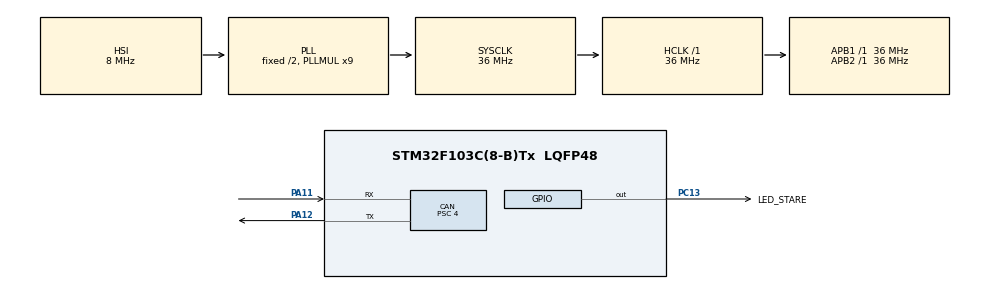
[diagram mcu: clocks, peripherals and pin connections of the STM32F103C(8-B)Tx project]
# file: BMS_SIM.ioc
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CAN.BS1=CAN_BS1_15TQ
CAN.BS2=CAN_BS2_2TQ
CAN.CalculateBaudRate=500000
CAN.CalculateTimeBit=2000
CAN.CalculateTimeQuantum=111.11111111111111
CAN.Prescaler=4
Mcu.Family=STM32F1
Mcu.Name=STM32F103C(8-B)Tx
Mcu.Package=LQFP48
NVIC.CAN1_RX1_IRQn=true\:0\:0\:false\:false\:true\:true\:true\:true
NVIC.CAN1_SCE_IRQn=true\:0\:0\:false\:false\:true\:true\:true\:true
NVIC.PriorityGroup=NVIC_PRIORITYGROUP_4
NVIC.TIM2_IRQn=true\:0\:0\:false\:false\:true\:true\:true\:true
NVIC.TIM3_IRQn=true\:0\:0\:false\:false\:true\:true\:true\:true
NVIC.USB_HP_CAN1_TX_IRQn=true\:0\:0\:false\:false\:true\:true\:true\:true
NVIC.USB_LP_CAN1_RX0_IRQn=true\:0\:0\:false\:false\:true\:true\:true\:true
PA11.Mode=CAN_Activate
PA11.Signal=CAN_RX
PA12.Mode=CAN_Activate
PA12.Signal=CAN_TX
PC13-TAMPER-RTC.GPIO_Label=LED_STARE
PC13-TAMPER-RTC.Signal=GPIO_Output
ProjectManager.HeapSize=0x200
ProjectManager.StackSize=0x400
ProjectManager.TargetToolchain=STM32CubeIDE
RCC.AHBFreq_Value=36000000
RCC.APB1Freq_Value=36000000
RCC.APB1TimFreq_Value=36000000
RCC.APB2Freq_Value=36000000
RCC.APB2TimFreq_Value=36000000
RCC.HCLKFreq_Value=36000000
RCC.PLLMUL=RCC_PLL_MUL9
RCC.SYSCLKFreq_VALUE=36000000
RCC.SYSCLKSource=RCC_SYSCLKSOURCE_PLLCLK
RCC.USBFreq_Value=36000000
TIM2.Period=49999
TIM2.Prescaler=399
TIM3.Period=44999
TIM3.Prescaler=399
VP_SYS_VS_ND.Mode=No_Debug
VP_TIM2_VS_ClockSourceINT.Mode=Internal
VP_TIM3_VS_ClockSourceINT.Mode=Internal
board=custom

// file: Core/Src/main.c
/* USER CODE BEGIN Header */
/**
 ******************************************************************************
 * @file           : main.c
 * @brief          : Main program body
 ******************************************************************************
 * @attention
 *
 * Copyright (c) 2025 STMicroelectronics.
 * All rights reserved.
 *
 * This software is licensed under terms that can be found in the LICENSE file
 * in the root directory of this software component.
 * If no LICENSE file comes with this software, it is provided AS-IS.
 *
 ******************************************************************************
 */
/* USER CODE END Header */
#include "main.h"

/* USER CODE BEGIN Includes */
#include <stdbool.h>
/* USER CODE END Includes */

CAN_HandleTypeDef hcan;

TIM_HandleTypeDef htim2;
TIM_HandleTypeDef htim3;

/* USER CODE BEGIN PV */
volatile bool tim2_flag_b = 0;
volatile bool tim3_flag_b = 0;
/* USER CODE END PV */

void SystemClock_Config(void);
static void MX_GPIO_Init(void);
static void MX_TIM2_Init(void);
static void MX_TIM3_Init(void);
static void MX_CAN_Init(void);

/* USER CODE BEGIN 0 */
void CAN_TX(uint32_t StdId, uint32_t DLC, const uint8_t *Data) {
	CAN_TxHeaderTypeDef txheader;
	uint32_t txmailbox;

	txheader.DLC = DLC;
	txheader.StdId = StdId;
	txheader.IDE = CAN_ID_STD;
	txheader.RTR = CAN_RTR_DATA;

	if (HAL_CAN_AddTxMessage(&hcan, &txheader, Data, &txmailbox) != HAL_OK) {
		Error_Handler();
	}
}
/* USER CODE END 0 */

int main(void)
{

  /* MCU Configuration--------------------------------------------------------*/

  /* Reset of all peripherals, Initializes the Flash interface and the Systick. */
  HAL_Init();

  /* Configure the system clock */
  SystemClock_Config();

  /* Initialize all configured peripherals */
  MX_GPIO_Init();
  MX_TIM2_Init();
  MX_TIM3_Init();
  MX_CAN_Init();
  /* USER CODE BEGIN 2 */
	if (HAL_CAN_ActivateNotification(&hcan,
		CAN_IT_TX_MAILBOX_EMPTY | CAN_IT_RX_FIFO0_MSG_PENDING | CAN_IT_BUSOFF)
				!= HAL_OK) {
			Error_Handler();
		}

		if (HAL_CAN_Start(&hcan) != HAL_OK) {
			Error_Handler();
		}
	HAL_TIM_Base_Start_IT(&htim2);
	HAL_TIM_Base_Start_IT(&htim3);

  /* USER CODE END 2 */

  /* Infinite loop */
	while (1) {

    /* USER CODE BEGIN 3 */
		if (tim2_flag_b == 1) {
			HAL_GPIO_TogglePin(LED_STARE_GPIO_Port, LED_STARE_Pin);

			uint8_t Data_100[8] = {
			    0x01, 0xF4,  // Voltage (500 -> 50.0V)
			    0x00, 0x64,  // Current (100 -> 10.0A)
			    0x50,        // SOC (80%)
			    0x63,        // SOH (99%)
			    0xFA,        // AmpHours (250 -> 25.0Ah)
			    0x0E         // CRC Checksum
			};
			CAN_TX(0x100, 8, Data_100);

			tim2_flag_b = 0;
		}
		if (tim3_flag_b == 1) {
			HAL_GPIO_TogglePin(LED_STARE_GPIO_Port, LED_STARE_Pin);
			uint8_t Data_101[8] = {
			    0x28,        // High Temp (40 C)
			    0x01,        // High ID
			    0x19,        // Low Temp (25 C)
			    0x02,        // Low ID
			    0x1E,        // Avg Temp (30 C)
			    0x05,        // Fan Speed
			    0x78,        // Fan Voltage (120 -> 12.0V)
			    0xE8         // CRC Checksum
			};
			CAN_TX(0x101, 8, Data_101);

			uint8_t Data_102[8] = {
			    0x00, 0x32,  // Resistance (50 mOhm)
			    0x02, 0x08,  // Max Pack Voltage (520 -> 52.0V)
			    0x96,        // Total Cycles (150)
			    0x23,        // Internal Temp (35 C)
			    0x03,        // Req Fan Speed
			    0x02         // CRC Checksum
			};
				CAN_TX(0x102, 8, Data_102);
				tim3_flag_b = 0;
			}

	}

  /* USER CODE END 3 */
}

void SystemClock_Config(void)
{
  RCC_OscInitTypeDef RCC_OscInitStruct = {0};
  RCC_ClkInitTypeDef RCC_ClkInitStruct = {0};

  /** Initializes the RCC Oscillators according to the specified parameters
  * in the RCC_OscInitTypeDef structure.
  */
  RCC_OscInitStruct.OscillatorType = RCC_OSCILLATORTYPE_HSI;
  RCC_OscInitStruct.HSIState = RCC_HSI_ON;
  RCC_OscInitStruct.HSICalibrationValue = RCC_HSICALIBRATION_DEFAULT;
  RCC_OscInitStruct.PLL.PLLState = RCC_PLL_ON;
  RCC_OscInitStruct.PLL.PLLSource = RCC_PLLSOURCE_HSI_DIV2;
  RCC_OscInitStruct.PLL.PLLMUL = RCC_PLL_MUL9;
  if (HAL_RCC_OscConfig(&RCC_OscInitStruct) != HAL_OK)
  {
    Error_Handler();
  }

  /** Initializes the CPU, AHB and APB buses clocks
  */
  RCC_ClkInitStruct.ClockType = RCC_CLOCKTYPE_HCLK|RCC_CLOCKTYPE_SYSCLK
                              |RCC_CLOCKTYPE_PCLK1|RCC_CLOCKTYPE_PCLK2;
  RCC_ClkInitStruct.SYSCLKSource = RCC_SYSCLKSOURCE_PLLCLK;
  RCC_ClkInitStruct.AHBCLKDivider = RCC_SYSCLK_DIV1;
  RCC_ClkInitStruct.APB1CLKDivider = RCC_HCLK_DIV1;
  RCC_ClkInitStruct.APB2CLKDivider = RCC_HCLK_DIV1;

  if (HAL_RCC_ClockConfig(&RCC_ClkInitStruct, FLASH_LATENCY_1) != HAL_OK)
  {
    Error_Handler();
  }
}

static void MX_CAN_Init(void)
{

  hcan.Instance = CAN1;
  hcan.Init.Prescaler = 4;
  hcan.Init.Mode = CAN_MODE_NORMAL;
  hcan.Init.SyncJumpWidth = CAN_SJW_1TQ;
  hcan.Init.TimeSeg1 = CAN_BS1_15TQ;
  hcan.Init.TimeSeg2 = CAN_BS2_2TQ;
  hcan.Init.TimeTriggeredMode = DISABLE;
  hcan.Init.AutoBusOff = DISABLE;
  hcan.Init.AutoWakeUp = DISABLE;
  hcan.Init.AutoRetransmission = DISABLE;
  hcan.Init.ReceiveFifoLocked = DISABLE;
  hcan.Init.TransmitFifoPriority = DISABLE;
  if (HAL_CAN_Init(&hcan) != HAL_OK)
  {
    Error_Handler();
  }

}

static void MX_TIM2_Init(void)
{

  TIM_ClockConfigTypeDef sClockSourceConfig = {0};
  TIM_MasterConfigTypeDef sMasterConfig = {0};

  htim2.Instance = TIM2;
  htim2.Init.Prescaler = 399;
  htim2.Init.CounterMode = TIM_COUNTERMODE_UP;
  htim2.Init.Period = 49999;
  htim2.Init.ClockDivision = TIM_CLOCKDIVISION_DIV1;
  htim2.Init.AutoReloadPreload = TIM_AUTORELOAD_PRELOAD_DISABLE;
  if (HAL_TIM_Base_Init(&htim2) != HAL_OK)
  {
    Error_Handler();
  }
  sClockSourceConfig.ClockSource = TIM_CLOCKSOURCE_INTERNAL;
  if (HAL_TIM_ConfigClockSource(&htim2, &sClockSourceConfig) != HAL_OK)
  {
    Error_Handler();
  }
  sMasterConfig.MasterOutputTrigger = TIM_TRGO_RESET;
  sMasterConfig.MasterSlaveMode = TIM_MASTERSLAVEMODE_DISABLE;
  if (HAL_TIMEx_MasterConfigSynchronization(&htim2, &sMasterConfig) != HAL_OK)
  {
    Error_Handler();
  }

}

static void MX_TIM3_Init(void)
{

  TIM_ClockConfigTypeDef sClockSourceConfig = {0};
  TIM_MasterConfigTypeDef sMasterConfig = {0};

  htim3.Instance = TIM3;
  htim3.Init.Prescaler = 399;
  htim3.Init.CounterMode = TIM_COUNTERMODE_UP;
  htim3.Init.Period = 44999;
  htim3.Init.ClockDivision = TIM_CLOCKDIVISION_DIV1;
  htim3.Init.AutoReloadPreload = TIM_AUTORELOAD_PRELOAD_DISABLE;
  if (HAL_TIM_Base_Init(&htim3) != HAL_OK)
  {
    Error_Handler();
  }
  sClockSourceConfig.ClockSource = TIM_CLOCKSOURCE_INTERNAL;
  if (HAL_TIM_ConfigClockSource(&htim3, &sClockSourceConfig) != HAL_OK)
  {
    Error_Handler();
  }
  sMasterConfig.MasterOutputTrigger = TIM_TRGO_RESET;
  sMasterConfig.MasterSlaveMode = TIM_MASTERSLAVEMODE_DISABLE;
  if (HAL_TIMEx_MasterConfigSynchronization(&htim3, &sMasterConfig) != HAL_OK)
  {
    Error_Handler();
  }

}

static void MX_GPIO_Init(void)
{
  GPIO_InitTypeDef GPIO_InitStruct = {0};

  /* GPIO Ports Clock Enable */
  __HAL_RCC_GPIOC_CLK_ENABLE();
  __HAL_RCC_GPIOA_CLK_ENABLE();

  /*Configure GPIO pin Output Level */
  HAL_GPIO_WritePin(LED_STARE_GPIO_Port, LED_STARE_Pin, GPIO_PIN_RESET);

  /*Configure GPIO pin : LED_STARE_Pin */
  GPIO_InitStruct.Pin = LED_STARE_Pin;
  GPIO_InitStruct.Mode = GPIO_MODE_OUTPUT_PP;
  GPIO_InitStruct.Pull = GPIO_NOPULL;
  GPIO_InitStruct.Speed = GPIO_SPEED_FREQ_LOW;
  HAL_GPIO_Init(LED_STARE_GPIO_Port, &GPIO_InitStruct);

}

/* USER CODE BEGIN 4 */
void HAL_TIM_PeriodElapsedCallback(TIM_HandleTypeDef *htim) { //Callback pentru timer
	if (htim->Instance == TIM2)
		tim2_flag_b = 1; //Modificarea flagului in true
	else if (htim->Instance == TIM3)
		tim3_flag_b = 1; //Modificarea flagului in true

}

/* USER CODE END 4 */

void Error_Handler(void)
{
	__disable_irq();
	while (1) {
	}
}
